# SAMA7D65D2GN8 register map
Vendor: Microchip Technology; Series: SAMA7D6; File version: 0
Registers are 32-bit, read-write, reset 0x0 unless marked. A register's access mark holds for its fields unless they carry their own. Offsets are from the block's base; [hi:lo] are bit positions; lines under a group give offsets from that group; {n}, {i} and the like mark numbered series; 'fields as' and 'values as' point back to an identical list.

## NICGPV0 — NIC-400 Global Programmers View
Base 0xE8B00000; register names take the prefix NICGPV_
Same registers: NICGPV1 0xE1500000
{0x2008+0x1000*i} NICGPV_AMIB_FN_MOD_BM_ISS[{i}] (i=0..13) group
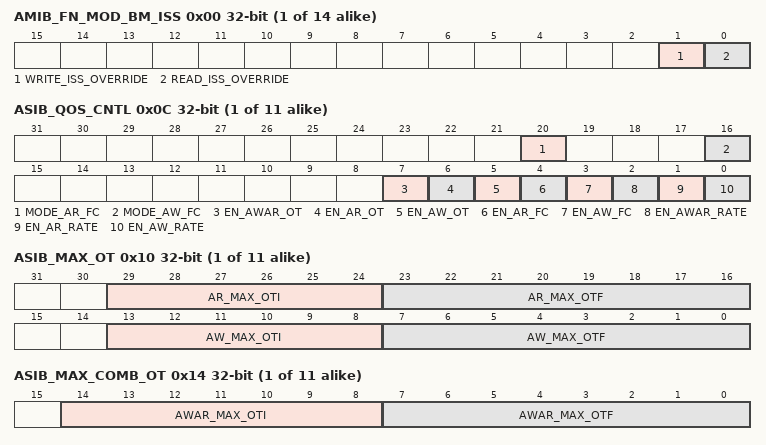
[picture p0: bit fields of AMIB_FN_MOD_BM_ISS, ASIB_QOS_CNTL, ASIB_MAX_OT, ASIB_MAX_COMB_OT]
  0x00 AMIB_FN_MOD_BM_ISS — AMIB Bus Matrix Issuing Functionality Modification Register
    [1] WRITE_ISS_OVERRIDE — Write Issuing Override
      0=No effect; 1=Write issuing capability is limited to one outstanding transaction
    [0] READ_ISS_OVERRIDE — Read Issuing Override
      0=No effect; 1=Read issuing capability is limited to one outstanding transaction
{0x42100+0x1000*i} NICGPV_ASIB[{i}] (i=0..10) group
  0x00 ASIB_READ_QOS — ASIB Read Channel QoS Register
    [3:0] RD_QOS — Read QoS
  0x04 ASIB_WRITE_QOS — ASIB Write Channel QoS Register
    [3:0] WR_QOS — Write QoS
  0x0C ASIB_QOS_CNTL — ASIB QoS Control Register
    [20] MODE_AR_FC — AR Feedback Control Mode
      0=TRANS_LAT (Transaction latency); 1=ADDR_LAT (Address latency)
    [16] MODE_AW_FC — AW Feedback Control Mode
      values as MODE_AR_FC
    [7] EN_AWAR_OT — AWAR Outstanding Transactions Enable
      0=DISABLED (Disable combined regulation of outstanding transactions.); 1=ENABLED (Enable combined regulation of outstanding transactions.)
    [6] EN_AR_OT — AR Outstanding Transactions Enable
      0=DISABLED (Disable regulation of outstanding read transactions.); 1=ENABLED (Enable regulation of outstanding read transactions.)
    [5] EN_AW_OT — AW Outstanding Transactions Enable
      0=DISABLED (Disable regulation of outstanding write transactions.); 1=ENABLED (Enable regulation of outstanding write transactions.)
    [4] EN_AR_FC — AR Feedback Control Enable
      0=DISABLED (Disable regulation of AR transaction or address latency.); 1=ENABLED (Enable regulation of AR transaction or address latency using feedback control, depending on the MODE_AR_FC setting.)
    [3] EN_AW_FC — AW Feedback Control Enable
      0=DISABLED (Disable regulation of AW transaction or address latency.); 1=ENABLED (Enable regulation of AW transaction or address latency using feedback control, depending on the MODE_AW_FC setting.)
    [2] EN_AWAR_RATE — AW and AR Rates Enable
      0=DISABLED (Disable combined AW and AR rate regulation.); 1=ENABLED (Enable combined AW and AR rate regulation.)
    [1] EN_AR_RATE — AR Rate Enable
      0=DISABLED (Disable AR rate regulation.); 1=ENABLED (Enable AR rate regulation.)
    [0] EN_AW_RATE — AW Rate Enable
      0=DISABLED (Disable AW rate regulation.); 1=ENABLED (Enable AW rate regulation.)
  0x10 ASIB_MAX_OT — ASIB Maximum Number of Outstanding Transactions Register
    [29:24] AR_MAX_OTI — AR Maximum Outstanding Transaction Integer
    [23:16] AR_MAX_OTF — AR Maximum Outstanding Transaction Fraction
    [13:8] AW_MAX_OTI — AW Maximum Outstanding Transaction Integer
    [7:0] AW_MAX_OTF — AW Maximum Outstanding Transaction Fraction
  0x14 ASIB_MAX_COMB_OT — ASIB Maximum Combined Outstanding Transactions Register
    [14:8] AWAR_MAX_OTI — AW and AR Combined Maximum Outstanding Transactions Integer
    [7:0] AWAR_MAX_OTF — AW and AR Combined Maximum Outstanding Transactions Fraction
  0x18 ASIB_AW_P — ASIB Write Address Channel Peak Rate Register
    [31:24] AW_P — AW Channel Peak Rate
  0x1C ASIB_AW_B — ASIB Write Address Channel Burstiness Allowance Register
    [15:0] AW_B — AW Channel Burstiness
  0x20 ASIB_AW_R — ASIB Write Address Channel Average Rate Register
    [31:20] AW_R — AW Channel Average Rate
  0x24 ASIB_AR_P — ASIB Read Address Channel Peak Rate Register
    [31:24] AR_P — AR Channel Peak Rate
  0x28 ASIB_AR_B — ASIB Read Address Channel Burstiness Allowance Register
    [15:0] AR_B — AR Channel Burstiness
  0x2C ASIB_AR_R — ASIB Read Address Channel Average Rate Register
    [31:20] AR_R — AR Channel Average Rate
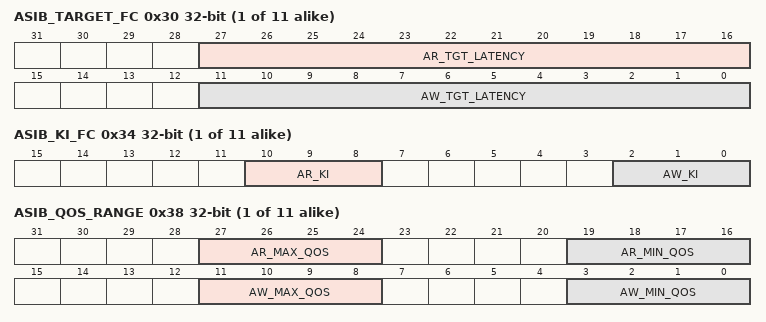
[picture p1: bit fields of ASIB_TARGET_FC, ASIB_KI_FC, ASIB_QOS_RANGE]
  0x30 ASIB_TARGET_FC — ASIB Feedback Controlled Target Register
    [27:16] AR_TGT_LATENCY — AR Channel Target Latency
    [11:0] AW_TGT_LATENCY — AW Channel Target Latency
  0x34 ASIB_KI_FC — ASIB Feedback Controlled Scale Register
    [10:8] AR_KI — AW QOS Scale Factor
      {v}=TWO_POW_M{v+3} (2-{v+3}) (v=0..7)
    [2:0] AW_KI — AR QOS Scale Factor
      {v}=TWO_POW_M{v+3} (2-{v+3}) (v=0..7)
  0x38 ASIB_QOS_RANGE
    [27:24] AR_MAX_QOS — AR Maximum QOS
    [19:16] AR_MIN_QOS — AR Minimum QOS
    [11:8] AW_MAX_QOS — AW Maximum QOS
    [3:0] AW_MIN_QOS — AW Minimum QOS
{0xC2008+0x1000*i} NICGPV_IB[{i}] (i=0..1) group
  0x00 IB_FN_MOD_BM_ISS — IB Bus Matrix Issuing Functionality Modification Register
    [1:0] FN_MODE — Issuing Functionality
      0=READ_ISS_OVERRIDE (Read issuing); 1=WRITE_ISS_OVERRIDE (Write issuing)
  0x18 IB_SYNC_MODE reset 0x4 — IB Clock Boundary Synchronization Scheme Register
    [2:0] SYNC_MODE — Read Issuing
      0=SYNC_1_TO_1 (Sync 1:1); 1=SYNC_M_TO_1 (Sync m:1); 2=SYNC_1_TO_N (Sync 1:n); 3=SYNC_M_TO_N (Sync m:n); 4=ASYNC
  0x1C IB_FN_MOD2_BP_MRG — IB Bypass Merge register
    [0] BP_MRG — Bypass Merge
  0x24 IB_FN_MOD_LB — IB Long Burst Functionality Modification Register
    [0] LB_MODE — Long Burst Mode
      0=DISABLED (Long bursts cannot be generated at the output of the interface bus.); 1=ENABLED (Long bursts can be generated at the output of the interface bus.)
  0x38 IB_WR_TIDEMARK reset 0x2 — IB Tidemark Register
    [3:0] WR_TIDEMARK — WR Tidemark Value
  0x100 IB_FN_MOD — IB Issuing Functionality Modification Register
    [1:0] FN_MODE — Issuing Functionality Mode
      values as NICGPV_IB[0].IB_FN_MOD_BM_ISS.FN_MODE
